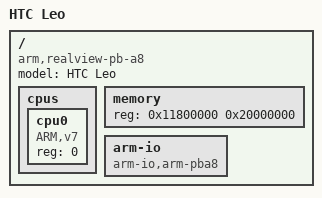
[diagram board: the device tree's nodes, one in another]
/*
 * ARM HTC HD2 DeviceTree.
 */

#include "Skeleton.dtsi"

/ {
    compatible = "arm,realview-pb-a8", "AppleARM";
    model = "HTC Leo";
    #address-cells = <1>;
    #size-cells = <1>;
    //interrupt-parent = <&intc>;

    /*
     * CPU nodes. (Cortex-A8)
     */
    cpus {
        #address-cells = <1>;
        #size-cells = <0>;
        cpu0 {
            device_type = "cpu";
            compatible = "ARM,v7", "ARM,cortex-a8";
            reg = <0>;
        };
    };

    memory {
        device_type = "memory";
        reg = <0x11800000 0x20000000>; /* 512 MB for now*/
    };

    /*
     * ARM IO bus.
     */
    arm-io {
        device_type = "arm-io";
        compatible = "arm-io,arm-pba8";
        #address-cells = <1>;
        #size-cells = <1>;
        
        /*intc: interrupt-controller {
            compatible = "arm,realview-gic", "arm,primecell";
            device_type = "interrupt-controller";
            interrupt-controller;
            reg = <0x1e000000 0x1000>;
            #interrupt-cells = <1>;
        };*/

        /*
         * System UARTs
         */

        /*
         * System timers.
         *
        timer0 {
            compatible = "arm,sp804", "arm,primecell";
            device_type = "timer";
            reg = <0x10011000 0x1000>;
            clock-frequency = <32768>;
            AAPL,interrupts = <36>;
        };*/

        /*
         * Display controller.
         */

        /*
         * Misc devices.
         */
    };
};
